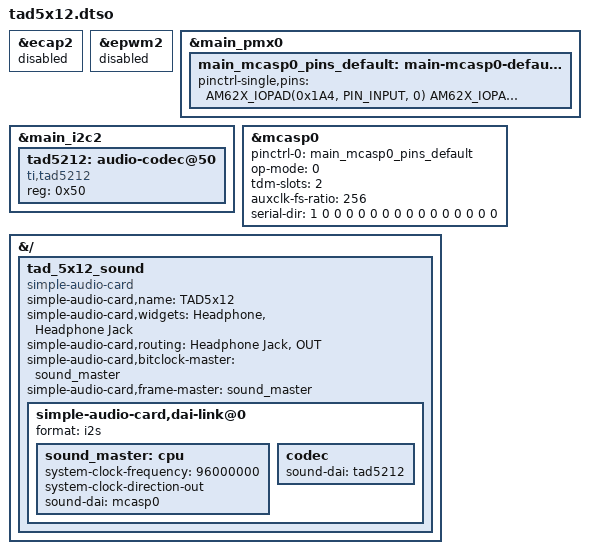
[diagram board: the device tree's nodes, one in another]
/dts-v1/;
/plugin/;

#include <dt-bindings/gpio/gpio.h>
#include <dt-bindings/interrupt-controller/irq.h>
#include <ti/k3-pinctrl.h>

/* pinctrl-single f4000.pinctrl: pin PIN105 already requested by 23120000.pwm; cannot claim for 2b00000.audio-controller */
&ecap2 {
        status = "disabled";
};
&epwm2 {
        status = "disabled";
};

&main_pmx0 {
        main_mcasp0_pins_default: main-mcasp0-default-pins {
                pinctrl-single,pins = <
                        AM62X_IOPAD(0x1A4, PIN_INPUT, 0) /* (B20/C17) MCASP0_ACLKX.MCASP0_ACLKX */
                        AM62X_IOPAD(0x1A8, PIN_INPUT, 0) /* (D20/C16) MCASP0_AFSX.MCASP0_AFSX */
                        AM62X_IOPAD(0x1A0, PIN_OUTPUT, 0) /* (E18/D18) MCASP0_AXR0.MCASP0_AXR0 */
                >;
        };
};

&main_i2c2 {
        #address-cells = <1>;
        #size-cells = <0>;

        tad5212: audio-codec@50 {
                compatible = "ti,tad5212";
                reg = <0x50>;
                #sound-dai-cells = <0>;
        };
};

&mcasp0 {
        status = "okay";
        #sound-dai-cells = <0>;

        pinctrl-names = "default";
        pinctrl-0 = <&main_mcasp0_pins_default>;

        op-mode = <0>;          /* MCASP_IIS_MODE */
        tdm-slots = <2>;
        auxclk-fs-ratio = <256>;
        serial-dir = <  /* 0: INACTIVE, 1: TX, 2: RX */
                1 0 0 0
                0 0 0 0
                0 0 0 0
                0 0 0 0
        >;
};

&{/} {
        tad_5x12_sound {
                compatible = "simple-audio-card";
                simple-audio-card,name = "TAD5x12";
                simple-audio-card,widgets =
                        "Headphone", "Headphone Jack";
                simple-audio-card,routing =
                        "Headphone Jack", "OUT";
                simple-audio-card,bitclock-master = <&sound_master>;
                simple-audio-card,frame-master = <&sound_master>;

                simple-audio-card,dai-link@0 {
                        format = "i2s";
                        sound_master: cpu {
                                system-clock-frequency = <96000000>;
                                system-clock-direction-out;
                                sound-dai = <&mcasp0>;
                        };

                        codec {
                                sound-dai = <&tad5212>;
                        };
                };
        };
};
